VERSION ""

NS_ :

BS_:

BU_: Engine_ECU Transmission_ECU Dashboard_Display Sensor_Cluster Brake_ECU

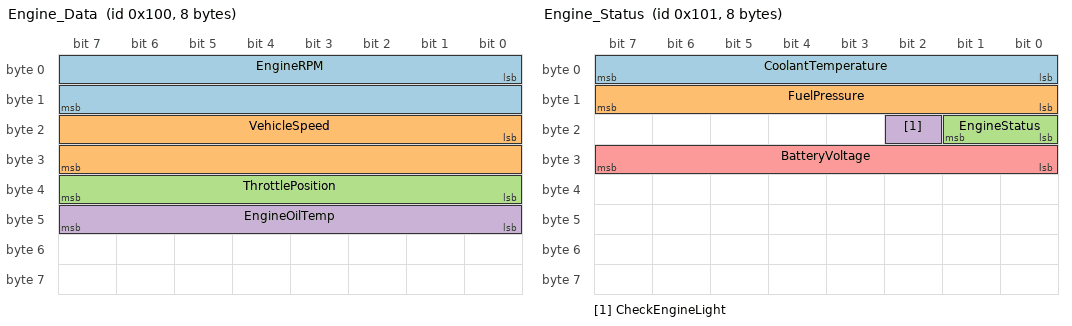
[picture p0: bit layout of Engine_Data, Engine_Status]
BO_ 256 Engine_Data: 8 Engine_ECU
 SG_ EngineRPM : 0|16@1+ (0.25,0) [0|16383.75] "rpm" Dashboard_Display
 SG_ VehicleSpeed : 16|16@1+ (0.01,0) [0|655.35] "km/h" Dashboard_Display
 SG_ ThrottlePosition : 32|8@1+ (0.392157,0) [0|100] "%" Engine_ECU
 SG_ EngineOilTemp : 40|8@1+ (1,-40) [-40|215] "degC" Dashboard_Display

BO_ 257 Engine_Status: 8 Engine_ECU
 SG_ CoolantTemperature : 0|8@1+ (1,-40) [-40|215] "degC" Dashboard_Display
 SG_ FuelPressure : 8|8@1+ (4,0) [0|1020] "kPa" Engine_ECU
 SG_ EngineStatus : 16|2@1+ (1,0) [0|3] "" Dashboard_Display
 SG_ CheckEngineLight : 18|1@1+ (1,0) [0|1] "" Dashboard_Display
 SG_ BatteryVoltage : 24|8@1+ (0.1,0) [0|25.5] "V" Dashboard_Display

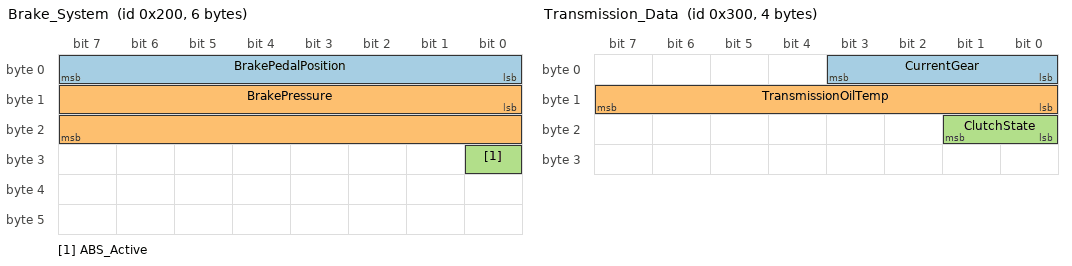
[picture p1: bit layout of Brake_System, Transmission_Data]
BO_ 512 Brake_System: 6 Brake_ECU
 SG_ BrakePedalPosition : 0|8@1+ (0.392157,0) [0|100] "%" Dashboard_Display
 SG_ BrakePressure : 8|16@1+ (0.1,0) [0|6553.5] "bar" Dashboard_Display
 SG_ ABS_Active : 24|1@1+ (1,0) [0|1] "" Dashboard_Display

BO_ 768 Transmission_Data: 4 Transmission_ECU
 SG_ CurrentGear : 0|4@1+ (1,0) [0|15] "" Dashboard_Display
 SG_ TransmissionOilTemp : 8|8@1+ (1,-40) [-40|215] "degC" Dashboard_Display
 SG_ ClutchState : 16|2@1+ (1,0) [0|3] "" Dashboard_Display

CM_ BO_ 256 "Primary powertrain dynamic metrics broadcast from Engine ECU at 50Hz";
CM_ SG_ 256 EngineRPM "Current engine rotational speed in revolutions per minute";
CM_ SG_ 256 VehicleSpeed "Calculated vehicle forward velocity";
CM_ SG_ 256 ThrottlePosition "Accelerator pedal / throttle valve position percentage";
CM_ SG_ 256 EngineOilTemp "Engine oil temperature in Celsius";
CM_ BO_ 257 "Powertrain health status and electrical indicators broadcast at 10Hz";
CM_ SG_ 257 CoolantTemperature "Engine cylinder block coolant temperature";
CM_ SG_ 257 FuelPressure "High-pressure fuel rail gauge pressure";
CM_ SG_ 257 EngineStatus "0=Off, 1=Running, 2=Cranking, 3=Fault";
CM_ SG_ 257 CheckEngineLight "MIL warning lamp state (0=Off, 1=Active)";
CM_ SG_ 257 BatteryVoltage "Vehicle 12V electrical bus rail voltage";
CM_ BO_ 512 "Electronic brake control module telemetry broadcast at 50Hz";
CM_ SG_ 512 BrakePedalPosition "Driver brake pedal application percentage";
CM_ SG_ 512 BrakePressure "Hydraulic master cylinder brake line pressure";
CM_ SG_ 512 ABS_Active "Anti-lock braking system intervention flag";
CM_ BO_ 768 "Automatic/DCT transmission status broadcast at 20Hz";
CM_ SG_ 768 CurrentGear "Currently engaged transmission gear (0=N, 1-6=Gears, 7=R)";
CM_ SG_ 768 TransmissionOilTemp "Transmission fluid temperature in Celsius";
CM_ SG_ 768 ClutchState "0=Open, 1=Slipping, 2=Closed, 3=Fault";
